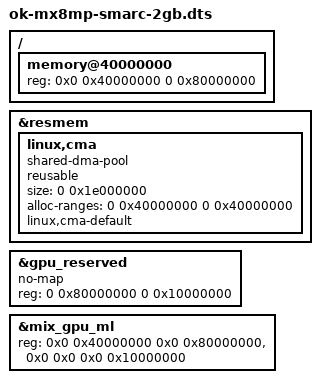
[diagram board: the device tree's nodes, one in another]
/*
 * Copyright 2024 FORLINX
 */

#include "ok-mx8mp-smarc.dts"

/ {
	memory@40000000 {
		device_type = "memory";
		reg = <0x0 0x40000000 0 0x80000000>;
	};
};

&resmem {
	/* global autoconfigured region for contiguous allocations */
	linux,cma {
		compatible = "shared-dma-pool";
		reusable;
		size = <0 0x1e000000>;
		alloc-ranges = <0 0x40000000 0 0x40000000>;
		linux,cma-default;
	};
};

&gpu_reserved {
	no-map;
	reg = <0 0x80000000 0 0x10000000>;
};

&mix_gpu_ml {
	reg = <0x0 0x40000000 0x0 0x80000000>, <0x0 0x0 0x0 0x10000000>;
	status = "okay";
};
